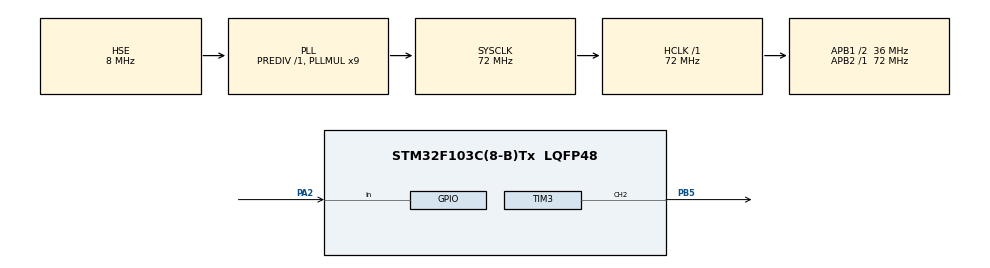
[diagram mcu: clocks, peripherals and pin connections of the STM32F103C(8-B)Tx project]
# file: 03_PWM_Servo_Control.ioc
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Mcu.Family=STM32F1
Mcu.Name=STM32F103C(8-B)Tx
Mcu.Package=LQFP48
NVIC.PriorityGroup=NVIC_PRIORITYGROUP_4
PA2.GPIO_PuPd=GPIO_PULLUP
PA2.Signal=GPIO_Input
PB5.Signal=S_TIM3_CH2
PD0-OSC_IN.Mode=HSE-External-Oscillator
PD0-OSC_IN.Signal=RCC_OSC_IN
PD1-OSC_OUT.Mode=HSE-External-Oscillator
PD1-OSC_OUT.Signal=RCC_OSC_OUT
ProjectManager.HeapSize=0x200
ProjectManager.StackSize=0x400
ProjectManager.TargetToolchain=STM32CubeIDE
RCC.AHBFreq_Value=72000000
RCC.APB1CLKDivider=RCC_HCLK_DIV2
RCC.APB1Freq_Value=36000000
RCC.APB1TimFreq_Value=72000000
RCC.APB2Freq_Value=72000000
RCC.APB2TimFreq_Value=72000000
RCC.HCLKFreq_Value=72000000
RCC.PLLMUL=RCC_PLL_MUL9
RCC.PLLSourceVirtual=RCC_PLLSOURCE_HSE
RCC.SYSCLKFreq_VALUE=72000000
RCC.SYSCLKSource=RCC_SYSCLKSOURCE_PLLCLK
RCC.USBFreq_Value=72000000
SH.S_TIM3_CH2.0=TIM3_CH2,PWM Generation2 CH2
TIM3.AutoReloadPreload=TIM_AUTORELOAD_PRELOAD_ENABLE
TIM3.Channel-PWM\ Generation2\ CH2=TIM_CHANNEL_2
TIM3.Period=19999
TIM3.Prescaler=71
VP_SYS_VS_ND.Mode=No_Debug
VP_TIM3_VS_ClockSourceINT.Mode=Internal
board=custom

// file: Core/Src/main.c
/* USER CODE BEGIN Header */
/**
  ******************************************************************************
  * @file           : main.c
  * @brief          : Main program body
  ******************************************************************************
  * @attention
  *
  * Copyright (c) 2026 STMicroelectronics.
  * All rights reserved.
  *
  * This software is licensed under terms that can be found in the LICENSE file
  * in the root directory of this software component.
  * If no LICENSE file comes with this software, it is provided AS-IS.
  *
  ******************************************************************************
  */
/* USER CODE END Header */
#include "main.h"
#include "tim.h"
#include "gpio.h"

/* USER CODE BEGIN PV */
uint8_t position_index = 0;
uint16_t angles[3] = {0, 90, 180};
uint32_t last_button_time = 0;
uint8_t last_button_state = 1;
/* USER CODE END PV */

void SystemClock_Config(void);

int main(void)
{

  /* MCU Configuration--------------------------------------------------------*/

  /* Reset of all peripherals, Initializes the Flash interface and the Systick. */
  HAL_Init();

  /* Configure the system clock */
  SystemClock_Config();

  /* Initialize all configured peripherals */
  MX_GPIO_Init();
  MX_TIM3_Init();
  /* USER CODE BEGIN 2 */
  /* Start PWM on TIM3 Channel 2 (PB5) */
    HAL_TIM_PWM_Start(&htim3, TIM_CHANNEL_2);

    /* Initial position = 0° */
    __HAL_TIM_SET_COMPARE(&htim3, TIM_CHANNEL_2, 1000);
  /* USER CODE END 2 */

  /* Infinite loop */
  while (1)
  {

    /* USER CODE BEGIN 3 */
	    uint8_t current_state = HAL_GPIO_ReadPin(GPIOA, GPIO_PIN_2);

	    // Detect falling edge
	    if (last_button_state == 1 && current_state == 0)
	    {
	        if (HAL_GetTick() - last_button_time > 200)
	        {
	            last_button_time = HAL_GetTick();

	            // غير الموضع
	            position_index++;
	            if (position_index > 2)
	                position_index = 0;

	            uint16_t angle = angles[position_index];

	            uint16_t pulse = 500 + (angle * 2000) / 180;

	            __HAL_TIM_SET_COMPARE(&htim3, TIM_CHANNEL_2, pulse);
	        }
	    }

	    last_button_state = current_state;
  }
  /* USER CODE END 3 */
}

void SystemClock_Config(void)
{
  RCC_OscInitTypeDef RCC_OscInitStruct = {0};
  RCC_ClkInitTypeDef RCC_ClkInitStruct = {0};

  /** Initializes the RCC Oscillators according to the specified parameters
  * in the RCC_OscInitTypeDef structure.
  */
  RCC_OscInitStruct.OscillatorType = RCC_OSCILLATORTYPE_HSE;
  RCC_OscInitStruct.HSEState = RCC_HSE_ON;
  RCC_OscInitStruct.HSEPredivValue = RCC_HSE_PREDIV_DIV1;
  RCC_OscInitStruct.HSIState = RCC_HSI_ON;
  RCC_OscInitStruct.PLL.PLLState = RCC_PLL_ON;
  RCC_OscInitStruct.PLL.PLLSource = RCC_PLLSOURCE_HSE;
  RCC_OscInitStruct.PLL.PLLMUL = RCC_PLL_MUL9;
  if (HAL_RCC_OscConfig(&RCC_OscInitStruct) != HAL_OK)
  {
    Error_Handler();
  }

  /** Initializes the CPU, AHB and APB buses clocks
  */
  RCC_ClkInitStruct.ClockType = RCC_CLOCKTYPE_HCLK|RCC_CLOCKTYPE_SYSCLK
                              |RCC_CLOCKTYPE_PCLK1|RCC_CLOCKTYPE_PCLK2;
  RCC_ClkInitStruct.SYSCLKSource = RCC_SYSCLKSOURCE_PLLCLK;
  RCC_ClkInitStruct.AHBCLKDivider = RCC_SYSCLK_DIV1;
  RCC_ClkInitStruct.APB1CLKDivider = RCC_HCLK_DIV2;
  RCC_ClkInitStruct.APB2CLKDivider = RCC_HCLK_DIV1;

  if (HAL_RCC_ClockConfig(&RCC_ClkInitStruct, FLASH_LATENCY_2) != HAL_OK)
  {
    Error_Handler();
  }
}

void Error_Handler(void)
{
  __disable_irq();
  while (1)
  {
  }
}
